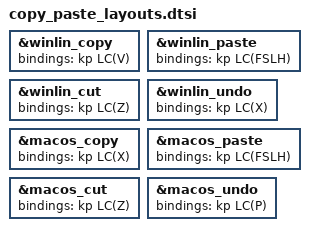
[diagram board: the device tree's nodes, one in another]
/*
 * OS-dependent clipboard/edit key overrides for custom Windows keyboard layouts.
 *
 * These layouts remap the letter positions, so the usual Ctrl+C/V/X/Z
 * (which ZMK sends from the physical QWERTY C/V/X/Z positions) no longer land
 * on the "C"/"V"/"X"/"Z" virtual keys. To keep copy/paste/cut/undo working we
 * instead press the physical key that produces that *character* under each
 * layout.
 *
 * The mapping below is derived from each layout's `scancode_to_vk` table:
 * we find the PC Set-1 scancode that maps to the target VK, then translate that
 * scancode back to the US-QWERTY physical key (= the ZMK keycode).
 *
 * Windows/Linux -> "Terminator" layout (kbdterm):
 *   VK 'C' @ scancode 0x2F -> physical US-QWERTY  V  (ZMK: V)
 *   VK 'V' @ scancode 0x35 -> physical US-QWERTY  /  (ZMK: FSLH)
 *   VK 'X' @ scancode 0x2C -> physical US-QWERTY  Z  (ZMK: Z)
 *   VK 'Z' @ scancode 0x2D -> physical US-QWERTY  X  (ZMK: X)
 *
 * macOS slot -> "Neu" layout (kbdneu). Note: uses the Ctrl (LC) modifier too,
 * per request -- no Cmd/GUI -- only the physical key positions differ:
 *   VK 'C' @ scancode 0x2D -> physical US-QWERTY  X  (ZMK: X)
 *   VK 'V' @ scancode 0x35 -> physical US-QWERTY  /  (ZMK: FSLH)
 *   VK 'X' @ scancode 0x2C -> physical US-QWERTY  Z  (ZMK: Z)
 *   VK 'Z' @ scancode 0x19 -> physical US-QWERTY  P  (ZMK: P)
 *
 * These amend the macro nodes declared in the board's behaviors_macros.dtsi,
 * which the bistable bst_copy/bst_paste/bst_cut/bst_undo behaviors dispatch to.
 */

&winlin_copy {
	bindings = <&kp LC(V)>;
};

&winlin_paste {
	bindings = <&kp LC(FSLH)>;
};

&winlin_cut {
	bindings = <&kp LC(Z)>;
};

&winlin_undo {
	bindings = <&kp LC(X)>;
};

&macos_copy {
	bindings = <&kp LC(X)>;
};

&macos_paste {
	bindings = <&kp LC(FSLH)>;
};

&macos_cut {
	bindings = <&kp LC(Z)>;
};

&macos_undo {
	bindings = <&kp LC(P)>;
};
